# APM32F446 register map
File version: 1.0
CPU: CM4 r0p1, little endian, MPU, FPU, 4 interrupt priority bits
Registers are 32-bit, read-write, reset 0x0 unless marked. A register's access mark holds for its fields unless they carry their own. Offsets are from the block's base; [hi:lo] are bit positions; 'fields as' and 'values as' point back to an identical list.

## LPI2C — The LPI2C Memory Map/Register Definition can be found here.
Base 0x40066000
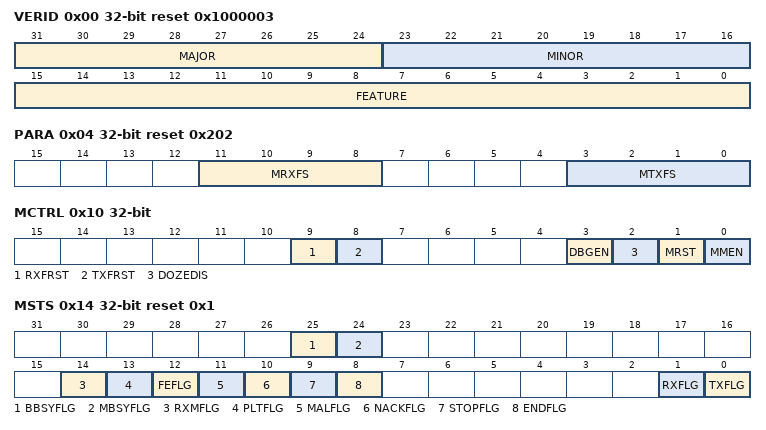
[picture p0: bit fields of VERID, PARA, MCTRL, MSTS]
0x00 VERID ro reset 0x1000003 — Version ID Register
  [31:24] MAJOR — Major Version Number
  [23:16] MINOR — Minor Version Number
  [15:0] FEATURE — Feature Number
    2=Master only with standard feature set; 3=Master and slave with standard feature set
0x04 PARA ro reset 0x202 — Parameter Register
  [11:8] MRXFS — Master Receive FIFO Size
  [3:0] MTXFS — Master Transmit FIFO Size
0x10 MCTRL — Master Control Register
  [9] RXFRST wo — Receive FIFO Reset
    0=No effect; 1=Receive FIFO is reset
  [8] TXFRST wo — Transmit FIFO Reset
    0=No effect; 1=Transmit FIFO is reset
  [3] DBGEN — Master Enabled in Debug Mode
    0=Master is disabled in debug mode; 1=Master is enabled in debug mode
  [2] DOZEDIS — Master Disabled in Doze Mode
    0=Master is enabled in Doze mode; 1=Master is disabled in Doze mode
  [1] MRST — Master Logic Software Reset
    0=Master logic is not reset; 1=Master logic is reset
  [0] MMEN — Master Mode Enable
    0=Master logic is disabled; 1=Master logic is enabled
0x14 MSTS reset 0x1 — Master Status Register
  [25] BBSYFLG ro — LPI2C Bus Busy Flag
    0=I2C Bus is idle; 1=I2C Bus is busy
  [24] MBSYFLG ro — LPI2C Master Busy Flag
    0=I2C Master is idle; 1=I2C Master is busy
  [14] RXMFLG — Received Data Match Flag
    0=Have not received matching data; 1=Have received matching data
  [13] PLTFLG — Pin Low Timeout Flag
    0=Pin low timeout has not occurred or is disabled; 1=Pin low timeout has occurred
  [12] FEFLG — FIFO Error Flag
    0=No error; 1=Master sending or receiving data without START condition
  [11] MALFLG — Master Arbitration Lost Flag
    0=Master has not lost arbitration; 1=Master has lost arbitration
  [10] NACKFLG — Unexpected NACK Detect Flag
    0=Unexpected NACK not detected; 1=Unexpected NACK was detected
  [9] STOPFLG — STOP Flag
    0=Master has not generated a STOP condition; 1=Master has generated a STOP condition
  [8] ENDFLG — End Flag
    0=Master has not generated a STOP or Repeated START condition; 1=Master has generated a STOP or Repeated START condition
  [1] RXFLG ro — Receive Data Flag
    0=Receive Data is not ready; 1=Receive data is ready
  [0] TXFLG ro — Transmit Data Flag
    0=Transmit data not requested; 1=Transmit data is requested
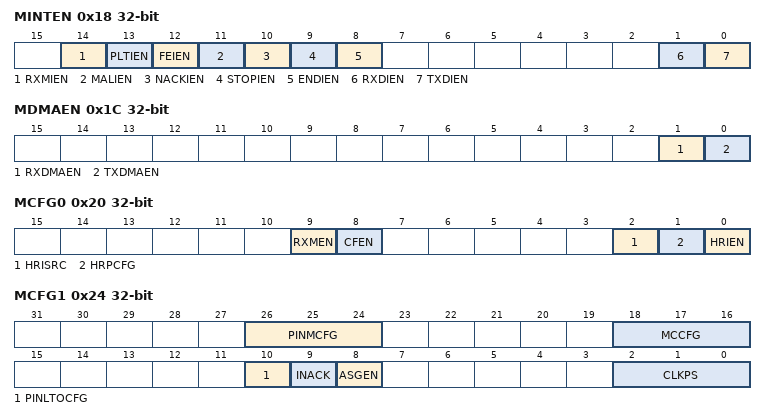
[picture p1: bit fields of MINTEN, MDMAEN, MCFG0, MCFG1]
0x18 MINTEN — Master Interrupt Enable Register
  [14] RXMIEN — Received Data Match Interrupt Enable
    0=Interrupt disabled; 1=Interrupt enabled
  [13] PLTIEN — Pin Low Timeout Interrupt Enable
    0=Interrupt disabled; 1=Interrupt enabled
  [12] FEIEN — FIFO Error Interrupt Enable
    0=Interrupt enabled; 1=Interrupt disabled
  [11] MALIEN — Master Arbitration Lost Interrupt Enable
    0=Interrupt disabled; 1=Interrupt enabled
  [10] NACKIEN — Unexpected NACK Detect Interrupt Enable
    0=Interrupt disabled; 1=Interrupt enabled
  [9] STOPIEN — STOP Detect Interrupt Enable
    0=Interrupt disabled; 1=Interrupt enabled
  [8] ENDIEN — End Packet Interrupt Enable
    0=Interrupt disabled; 1=Interrupt enabled
  [1] RXDIEN — Receive Data Interrupt Enable
    0=Interrupt disabled; 1=Interrupt enabled
  [0] TXDIEN — Transmit Data Interrupt Enable
    0=Interrupt disabled; 1=Interrupt enabled
0x1C MDMAEN — Master DMA Enable Register
  [1] RXDMAEN — Receive Data DMA Enable
    0=DMA request disabled; 1=DMA request enabled
  [0] TXDMAEN — Transmit Data DMA Enable
    0=DMA request disabled; 1=DMA request enabled
0x20 MCFG0 — Master Configure Register 0
  [9] RXMEN — Receive Data Match Enable
    0=Received data is stored in the receive FIFO as normal; 1=Received data is discarded unless the RMF is set
  [8] CFEN — Circular FIFO Enable
    0=Circular FIFO is disabled; 1=Circular FIFO is enabled
  [2] HRISRC — Host Request Input Source Select
    0=Host request input is pin HREQ; 1=Host request input is input trigger
  [1] HRPCFG — Host Request Polarity Configure
    0=Active low; 1=Active high
  [0] HRIEN — Host Request Input Enable
    0=Host request input is disabled; 1=Host request input is enabled
0x24 MCFG1 — Master Configure Register 1
  [26:24] PINMCFG — Pin Mode Configure
    0=LPI2C configured for 2-pin open drain mode; 1=LPI2C configured for 2-pin output only mode (ultra-fast mode); 2=LPI2C configured for 2-pin push-pull mode; 3=LPI2C configured for 4-pin push-pull mode; 4=LPI2C configured for 2-pin open drain mode with separate LPI2C slave; 5=LPI2C configured for 2-pin output only mode (ultra-fast mode) with separate LPI2C slave; 6=LPI2C configured for 2-pin push-pull mode with separate LPI2C slave; 7=LPI2C configured for 4-pin push-pull mode (inverted outputs)
  [18:16] MCCFG — Match Condition Configure
    0=Match disabled; 2=Match enabled (1st data word equals VAL0 OR VAL1); 3=Match enabled (any data word equals VAL0 OR VAL1); 4=Match enabled (1st data word equals VAL0 AND 2nd data word equals VAL1); 5=Match enabled (any data word equals VAL0 AND next data word equals VAL1); 6=Match enabled (1st data word AND VAL1 equals VAL0 AND VAL1); 7=Match enabled (any data word AND VAL1 equals VAL0 AND VAL1)
  [10] PINLTOCFG — Pin Low Timeout Configure
    0=Pin Low Timeout Flag will set if SCL is low for longer than the configured timeout; 1=Pin Low Timeout Flag will set if either SCL or SDA is low for longer than the configured timeout
  [9] INACK — Ignore NACK
    0=LPI2C Master will receive ACK and NACK normally; 1=LPI2C Master will treat a received NACK as if it was an ACK
  [8] ASGEN — Automatic STOP Condition Generation
    0=No effect; 1=STOP condition is automatically generated whenever the transmit FIFO is empty and LPI2C master is busy
  [2:0] CLKPS — Clock Prescaler Configure
    0=Divide by 1; 1=Divide by 2; 2=Divide by 4; 3=Divide by 8; 4=Divide by 16; 5=Divide by 32; 6=Divide by 64; 7=Divide by 128
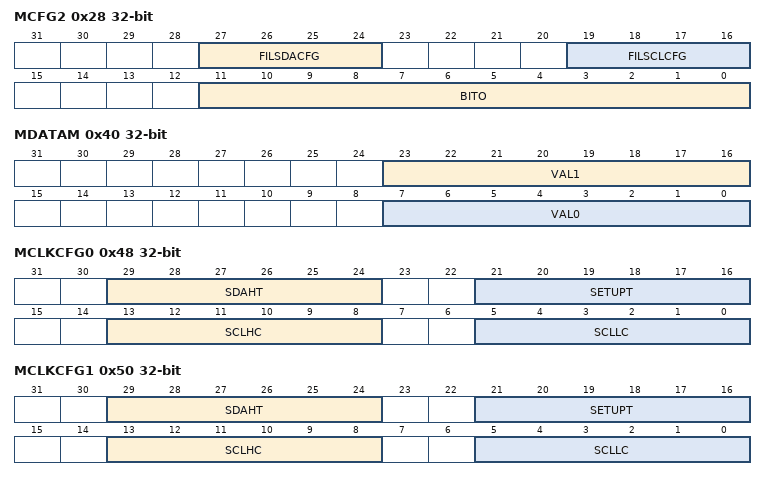
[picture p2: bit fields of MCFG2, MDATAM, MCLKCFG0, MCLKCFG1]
0x28 MCFG2 — Master Configure Register 2
  [27:24] FILSDACFG — Filter SDA Configure
  [19:16] FILSCLCFG — Filter SCL Configure
  [11:0] BITO — Bus Idle Timeout Value
0x2C MCFG3 — Master Configure Register 3
  [19:8] PLTO — Pin Low Timeout Flag Configure
0x40 MDATAM — Master Data Match Register
  [23:16] VAL1 — Compare Match 1 Value
  [7:0] VAL0 — Compare Match 0 Value
0x48 MCLKCFG0 — Master Clock Configure Register 0
  [29:24] SDAHT — Minimum Cycle of SDA Hold Time
  [21:16] SETUPT — Minimum Number of Cycles of Setup Time
  [13:8] SCLHC — SCL High Cycles
  [5:0] SCLLC — SCL Low Cycles
0x50 MCLKCFG1 — Master Clock Configure Register 1
  fields as MCLKCFG0
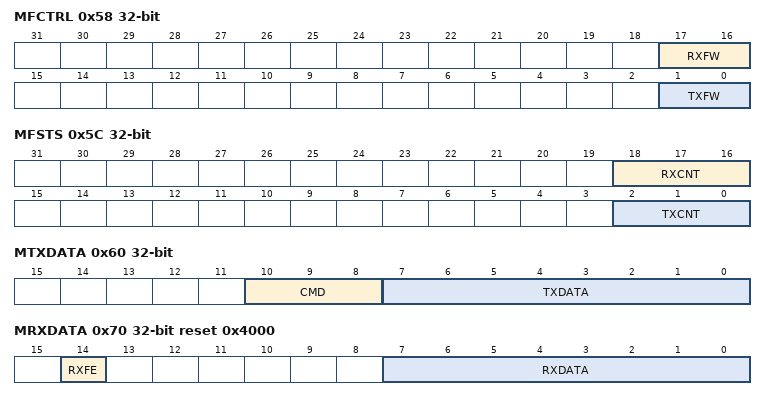
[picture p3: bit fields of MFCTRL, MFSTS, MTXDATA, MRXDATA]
0x58 MFCTRL — Master FIFO Control Register
  [17:16] RXFW — Receive FIFO Watermark
  [1:0] TXFW — Transmit FIFO Watermark
0x5C MFSTS ro — Master FIFO Status Register
  [18:16] RXCNT — Receive FIFO Count
  [2:0] TXCNT — Transmit FIFO Count
0x60 MTXDATA — Master Transmit Data Register
  [10:8] CMD wo — Command
    0=Transmit DATA[7:0]; 1=Receive (DATA[7:0] + 1) bytes; 2=Generate STOP condition; 3=Receive and discard (DATA[7:0] + 1) bytes; 4=Generate (repeated) START and transmit address in DATA[7:0]; 5=Generate (repeated) START and transmit address in DATA[7:0]. This transfer expects a NACK to be returned.; 6=Generate (repeated) START and transmit address in DATA[7:0] using high speed mode; 7=Generate (repeated) START and transmit address in DATA[7:0] using high speed mode. This transfer expects a NACK to be returned.
  [7:0] TXDATA wo — Transmit Data
0x70 MRXDATA ro reset 0x4000 — Master Receive Data Register
  [14] RXFE — Receive FIFO Empty
    0=Receive FIFO is not empty; 1=Receive FIFO is empty
  [7:0] RXDATA — Read Undiscarded Received Data
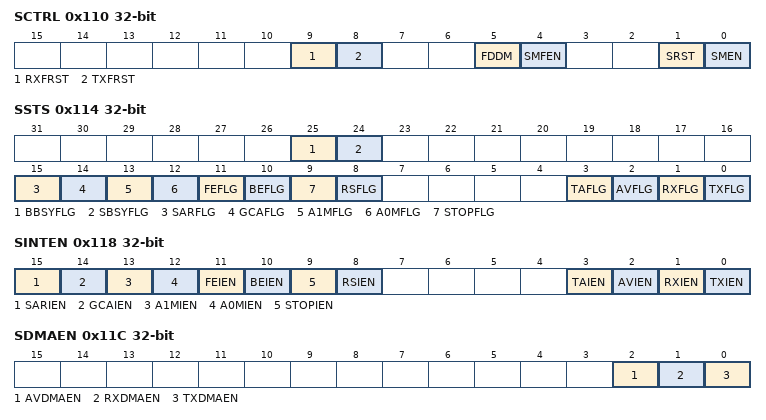
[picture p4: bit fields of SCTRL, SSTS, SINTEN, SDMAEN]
0x110 SCTRL — Slave Control Register
  [9] RXFRST wo — Receive FIFO Reset
    0=No effect; 1=Receive Data Register is now empty
  [8] TXFRST wo — Transmit FIFO Reset
    0=No effect; 1=Transmit Data Register is now empty
  [5] FDDM — Filter Disabled in Doze Mode
    0=Filter remains enabled in Doze mode; 1=Filter is disabled in Doze mode
  [4] SMFEN — Slave Mode Filter Enable
    0=Disable digital filter and output delay counter for slave mode; 1=Enable digital filter and output delay counter for slave mode
  [1] SRST — Slave Logic Software Reset
    0=Slave logic is not reset; 1=Slave logic is reset
  [0] SMEN — Slave Mode Enable
    0=Slave mode is disabled; 1=Slave mode is enabled
0x114 SSTS — Slave Status Register
  [25] BBSYFLG ro — LPI2C Bus Busy Flag
    0=I2C Bus is idle; 1=I2C Bus is busy
  [24] SBSYFLG ro — LPI2C Slave Busy Flag
    0=I2C Slave is idle; 1=I2C Slave is busy
  [15] SARFLG ro — SMBus Alert Response Flag
    0=SMBus Alert Response disabled or not detected; 1=SMBus Alert Response enabled and detected
  [14] GCAFLG ro — General Call Address Flag
    0=Slave has not detected the General Call Address or General Call Address disabled; 1=Slave has detected the General Call Address
  [13] A1MFLG ro — Address 1 Match Address Flag
    0=Have not received ADDR1 or ADDR0/ADDR1 range matching address; 1=Have received ADDR1 or ADDR0/ADDR1 range matching address
  [12] A0MFLG ro — Address 0 Match Address Flag
    0=Have not received ADDR0 matching address; 1=Have received ADDR0 matching address
  [11] FEFLG — FIFO Error Flag
    0=FIFO underflow or overflow not detected; 1=FIFO underflow or overflow detected
  [10] BEFLG — Bit Error Flag
    0=Slave has not detected a bit error; 1=Slave has detected a bit error
  [9] STOPFLG — STOP Detect Flag
    0=Slave has not detected a STOP condition; 1=Slave has detected a STOP condition
  [8] RSFLG — Repeated Start Flag
    0=Slave has not detected a Repeated START condition; 1=Slave has detected a Repeated START condition
  [3] TAFLG ro — Transmit ACK/NACK Flag
    0=Transmit ACK/NACK is not required; 1=Transmit ACK/NACK is required
  [2] AVFLG ro — Address Status Register Valid Flag
    0=Address Status Register is not valid; 1=Address Status Register is valid
  [1] RXFLG ro — Receive Data Flag
    0=Receive Data is not ready; 1=Receive data is ready
  [0] TXFLG ro — Transmit Data Flag
    0=Transmit data not requested; 1=Transmit data is requested
0x118 SINTEN — Slave Interrupt Enable Register
  [15] SARIEN — SMBus Alert Interrupt Enable
    0=Interrupt disabled; 1=Interrupt enabled
  [14] GCAIEN — General Call Interrupt Enable
    0=Interrupt disabled; 1=Interrupt enabled
  [13] A1MIEN — Address 1 Match Address Interrupt Enable
    0=Interrupt disabled; 1=Interrupt enabled
  [12] A0MIEN — Address 0 Match Address Interrupt Enable
    0=Interrupt enabled; 1=Interrupt disabled
  [11] FEIEN — FIFO Error Enable
    0=Interrupt disabled; 1=Interrupt enabled
  [10] BEIEN — Slave Bit Error Interrupt En
    0=Interrupt disabled; 1=Interrupt enabled
  [9] STOPIEN — Slave STOP Detect Interrupt Enable
    0=Interrupt disabled; 1=Interrupt enabled
  [8] RSIEN — Slave Repeated Start Interrupt Enable
    0=Interrupt disabled; 1=Interrupt enabled
  [3] TAIEN — Transmit ACK/NACK Interrupt Enable
    0=Interrupt disabled; 1=Interrupt enabled
  [2] AVIEN — Address Valid Interrupt Enable
    0=Interrupt disabled; 1=Interrupt enabled
  [1] RXIEN — Receive Data Interrupt Enable
    0=Interrupt disabled; 1=Interrupt enabled
  [0] TXIEN — Transmit Data Interrupt Enable
    0=Interrupt disabled; 1=Interrupt enabled
0x11C SDMAEN — Slave DMA Enable Register
  [all] fields
    0=DMA request disabled; 1=DMA request enabled
  [2] AVDMAEN — Address Valid DMA Enable
  [1] RXDMAEN — Receive Data DMA Enable
  [0] TXDMAEN — Transmit Data DMA Enable
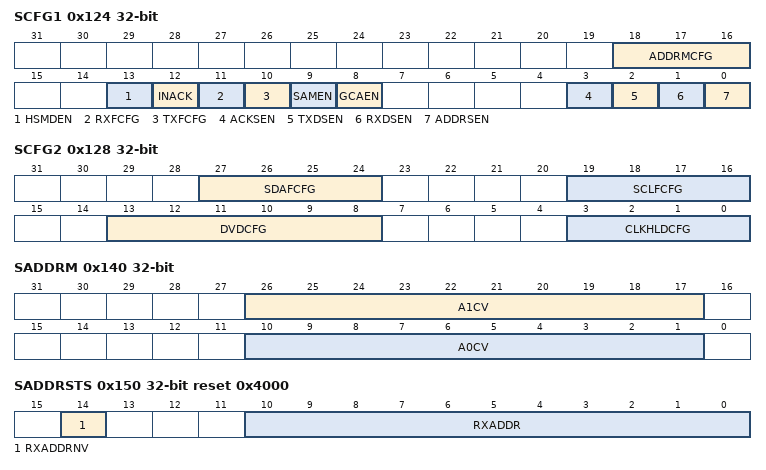
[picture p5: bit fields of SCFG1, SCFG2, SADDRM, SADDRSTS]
0x124 SCFG1 — Slave Configure Register 1
  [18:16] ADDRMCFG — Address Match Configure
    0=Address match 0 (7-bit); 1=Address match 0 (10-bit); 2=Address match 0 (7-bit) or Address match 1 (7-bit); 3=Address match 0 (10-bit) or Address match 1 (10-bit); 4=Address match 0 (7-bit) or Address match 1 (10-bit); 5=Address match 0 (10-bit) or Address match 1 (7-bit); 6=From Address match 0 (7-bit) to Address match 1 (7-bit); 7=From Address match 0 (10-bit) to Address match 1 (10-bit)
  [13] HSMDEN — High Speed Mode Detection Enable
    0=Disables detection of Hs-mode master code; 1=Enables detection of Hs-mode master code
  [12] INACK — Ignore NACK
    0=Slave will end transfer when NACK detected; 1=Slave will not end transfer when NACK detected
  [11] RXFCFG — Receive Data Flag Configure
    0=Reading the receive data register will return receive data and clear the receive data flag; 1=Reading the Receive Data register when the Address Valid flag (SSR[AVF])is set, will return the Address Status register and clear the Address Valid flag. Reading the Receive Data register when the Address Valid flag is clear, will return received data and clear the Receive Data flag (MSR[RDF]).
  [10] TXFCFG — Transmit Data Flag Configure
    0=Transmit Data Flag will only assert during a slave-transmit transfer when the transmit data register is empty; 1=Transmit Data Flag will assert whenever the transmit data register is empty
  [9] SAMEN — SMBus Alert Match Enable
    0=Disables match on SMBus Alert; 1=Enables match on SMBus Alert
  [8] GCAEN — General Call Address Enable
    0=General Call address is disabled; 1=General call address is enabled
  [3] ACKSEN — ACK SCL Stall Enable
    0=Clock stretching disabled; 1=Clock stretching enabled
  [2] TXDSEN — Transmit Data SCL Stall Enable
    0=Clock stretching disabled; 1=Clock stretching enabled
  [1] RXDSEN — Receive Data SCL Stall Enable
    0=Clock stretching disabled; 1=Clock stretching enabled
  [0] ADDRSEN — Address SCL Stall Enable
    0=Clock stretching disabled; 1=Clock stretching enabled
0x128 SCFG2 — Slave Configure Register 2
  [27:24] SDAFCFG — SDA Glitch Filter Configure
  [19:16] SCLFCFG — SCL Glitch Fliter Configure
  [13:8] DVDCFG — Data Valid Delay Configure
  [3:0] CLKHLDCFG — Clock Hold Time Configure
0x140 SADDRM — Slave Address Match Register
  [26:17] A1CV — Address1 Compare 1 Value
  [10:1] A0CV — Address0 Compare 0 Value
0x150 SADDRSTS ro reset 0x4000 — Slave Address Status Register
  [14] RXADDRNV — Received Address Not Vaild
    0=RXADDR is valid; 1=RXADDR is not valid
  [10:0] RXADDR — Received Address
0x154 STXACK — Slave Transmit ACK Register
  [0] TXNACK — Write a Transmit NACK
    0=Transmit ACK for received word; 1=Transmit NACK for received word
0x160 STXDATA — Slave Transmit Data Register
  [7:0] TXDATA wo — Slave Transmit Data
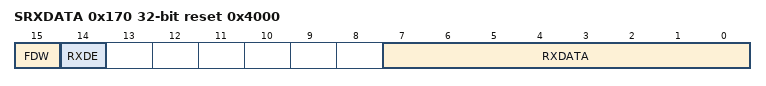
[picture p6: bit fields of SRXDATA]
0x170 SRXDATA ro reset 0x4000 — Slave Receive Data Register
  [15] FDW — First Data Word
    0=Indicates this is not the first data word since a (repeated) START or STOP condition; 1=Indicates this is the first data word since a (repeated) START or STOP condition
  [14] RXDE — Receive Data Register Empty
    0=The Receive Data Register is not empty; 1=The Receive Data Register is empty
  [7:0] RXDATA — Slave Received Data
